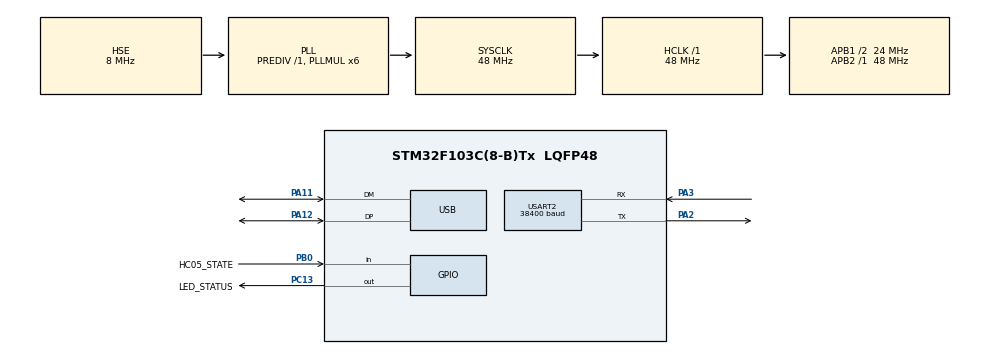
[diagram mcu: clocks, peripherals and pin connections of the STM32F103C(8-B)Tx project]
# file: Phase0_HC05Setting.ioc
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Mcu.Family=STM32F1
Mcu.Name=STM32F103C(8-B)Tx
Mcu.Package=LQFP48
NVIC.PriorityGroup=NVIC_PRIORITYGROUP_4
NVIC.USART2_IRQn=true\:5\:0\:true\:false\:true\:true\:true\:true
NVIC.USB_LP_CAN1_RX0_IRQn=true\:0\:0\:false\:false\:true\:false\:true\:true
PA11.Mode=Device
PA11.Signal=USB_DM
PA12.Mode=Device
PA12.Signal=USB_DP
PA13.Mode=Serial_Wire
PA13.Signal=SYS_JTMS-SWDIO
PA14.Mode=Serial_Wire
PA14.Signal=SYS_JTCK-SWCLK
PA2.Mode=Asynchronous
PA2.Signal=USART2_TX
PA3.Mode=Asynchronous
PA3.Signal=USART2_RX
PB0.GPIO_Label=HC05_STATE
PB0.GPIO_PuPd=GPIO_PULLDOWN
PB0.Signal=GPIO_Input
PC13-TAMPER-RTC.GPIO_Label=LED_STATUS
PC13-TAMPER-RTC.Signal=GPIO_Output
PD0-OSC_IN.Mode=HSE-External-Oscillator
PD0-OSC_IN.Signal=RCC_OSC_IN
PD1-OSC_OUT.Mode=HSE-External-Oscillator
PD1-OSC_OUT.Signal=RCC_OSC_OUT
ProjectManager.HeapSize=0x200
ProjectManager.StackSize=0x400
ProjectManager.TargetToolchain=CMake
RCC.AHBFreq_Value=48000000
RCC.APB1CLKDivider=RCC_HCLK_DIV2
RCC.APB1Freq_Value=24000000
RCC.APB1TimFreq_Value=48000000
RCC.APB2Freq_Value=48000000
RCC.APB2TimFreq_Value=48000000
RCC.HCLKFreq_Value=48000000
RCC.PLLMUL=RCC_PLL_MUL6
RCC.PLLSourceVirtual=RCC_PLLSOURCE_HSE
RCC.SYSCLKFreq_VALUE=48000000
RCC.SYSCLKSource=RCC_SYSCLKSOURCE_PLLCLK
RCC.USBFreq_Value=48000000
USART2.BaudRate=38400
USART2.VirtualMode=VM_ASYNC
USB_DEVICE.CLASS_NAME_FS=CDC
USB_DEVICE.VirtualMode=Cdc
USB_DEVICE.VirtualModeFS=Cdc_FS
VP_USB_DEVICE_VS_USB_DEVICE_CDC_FS.Mode=CDC_FS
board=custom

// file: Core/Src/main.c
/* USER CODE BEGIN Header */
/**
  ******************************************************************************
  * @file           : main.c
  * @brief          : Main program body.
  ******************************************************************************
  */
/* USER CODE END Header */
#include "main.h"
#include "usart.h"
#include "usb_device.h"
#include "gpio.h"

/* USER CODE BEGIN Includes */
#include "hc05_at.h"
/* USER CODE END Includes */

void SystemClock_Config(void);

int main(void)
{

  /* MCU Configuration--------------------------------------------------------*/

  /* Reset of all peripherals, Initializes the Flash interface and the Systick. */
  HAL_Init();

  /* Configure the system clock */
  SystemClock_Config();

  /* Initialize all configured peripherals */
  MX_GPIO_Init();
  MX_USART2_UART_Init();
  MX_USB_DEVICE_Init();
  /* USER CODE BEGIN 2 */
  HC05_AT_Init();

  /* USER CODE END 2 */

  /* Infinite loop */
  while (1)
  {

    /* USER CODE BEGIN 3 */
    HC05_AT_Process();
  }
  /* USER CODE END 3 */
}

void SystemClock_Config(void)
{
  RCC_OscInitTypeDef RCC_OscInitStruct = {0};
  RCC_ClkInitTypeDef RCC_ClkInitStruct = {0};
  RCC_PeriphCLKInitTypeDef PeriphClkInit = {0};

  /** Initializes the RCC Oscillators according to the specified parameters
  * in the RCC_OscInitTypeDef structure.
  */
  RCC_OscInitStruct.OscillatorType = RCC_OSCILLATORTYPE_HSE;
  RCC_OscInitStruct.HSEState = RCC_HSE_ON;
  RCC_OscInitStruct.HSEPredivValue = RCC_HSE_PREDIV_DIV1;
  RCC_OscInitStruct.HSIState = RCC_HSI_ON;
  RCC_OscInitStruct.PLL.PLLState = RCC_PLL_ON;
  RCC_OscInitStruct.PLL.PLLSource = RCC_PLLSOURCE_HSE;
  RCC_OscInitStruct.PLL.PLLMUL = RCC_PLL_MUL6;
  if (HAL_RCC_OscConfig(&RCC_OscInitStruct) != HAL_OK)
  {
    Error_Handler();
  }

  /** Initializes the CPU, AHB and APB buses clocks
  */
  RCC_ClkInitStruct.ClockType = RCC_CLOCKTYPE_HCLK|RCC_CLOCKTYPE_SYSCLK
                              |RCC_CLOCKTYPE_PCLK1|RCC_CLOCKTYPE_PCLK2;
  RCC_ClkInitStruct.SYSCLKSource = RCC_SYSCLKSOURCE_PLLCLK;
  RCC_ClkInitStruct.AHBCLKDivider = RCC_SYSCLK_DIV1;
  RCC_ClkInitStruct.APB1CLKDivider = RCC_HCLK_DIV2;
  RCC_ClkInitStruct.APB2CLKDivider = RCC_HCLK_DIV1;

  if (HAL_RCC_ClockConfig(&RCC_ClkInitStruct, FLASH_LATENCY_1) != HAL_OK)
  {
    Error_Handler();
  }
  PeriphClkInit.PeriphClockSelection = RCC_PERIPHCLK_USB;
  PeriphClkInit.UsbClockSelection = RCC_USBCLKSOURCE_PLL;
  if (HAL_RCCEx_PeriphCLKConfig(&PeriphClkInit) != HAL_OK)
  {
    Error_Handler();
  }
}

void Error_Handler(void)
{
  __disable_irq();
  while (1)
  {
  }
}
